# MB9BF12xJ register map
File version: 1.2
CPU: 
Registers are 8-bit, read-write, reset 0x0 unless marked. A register's access mark holds for its fields unless they carry their own. Offsets are from the block's base; [hi:lo] are bit positions; {n}, {i} and the like mark numbered series.

## EXTI — External Interrupt and NMI Control
Base 0x40030000
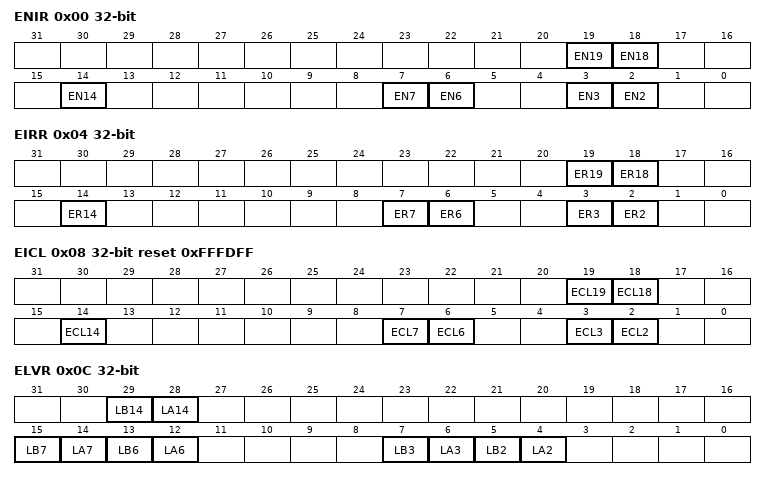
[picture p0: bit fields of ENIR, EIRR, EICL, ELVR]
0x00 ENIR 32-bit — Enable Interrupt Request Register
  [19] EN19 — Bit19 of ENIR
  [18] EN18 — Bit18 of ENIR
  [14] EN14 — Bit14 of ENIR
  [7] EN7 — Bit7 of ENIR
  [6] EN6 — Bit6 of ENIR
  [3] EN3 — Bit3 of ENIR
  [2] EN2 — Bit2 of ENIR
0x04 EIRR 32-bit ro reset not defined — External Interrupt Request Register
  [19] ER19 rw — Bit19 of EIRR
  [18] ER18 rw — Bit18 of EIRR
  [14] ER14 — Bit14 of EIRR
  [7] ER7 — Bit7 of EIRR
  [6] ER6 — Bit6 of EIRR
  [3] ER3 — Bit3 of EIRR
  [2] ER2 — Bit2 of EIRR
0x08 EICL 32-bit reset 0xFFFDFF — External Interrupt Clear Register
  [19] ECL19 — Bit19 of EICL
  [18] ECL18 — Bit18 of EICL
  [14] ECL14 — Bit14 of EICL
  [7] ECL7 — Bit7 of EICL
  [6] ECL6 — Bit6 of EICL
  [3] ECL3 — Bit3 of EICL
  [2] ECL2 — Bit2 of EICL
0x0C ELVR 32-bit — External Interrupt Level Register
  [29] LB14 — Bit29 of ELVR
  [28] LA14 — Bit28 of ELVR
  [15] LB7 — Bit15 of ELVR
  [14] LA7 — Bit14 of ELVR
  [13] LB6 — Bit13 of ELVR
  [12] LA6 — Bit12 of ELVR
  [7] LB3 — Bit7 of ELVR
  [6] LA3 — Bit6 of ELVR
  [5] LB2 — Bit5 of ELVR
  [4] LA2 — Bit4 of ELVR
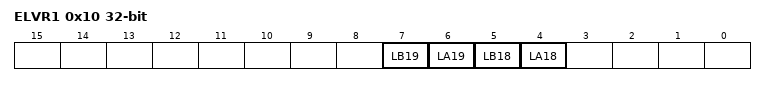
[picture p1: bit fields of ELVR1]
0x10 ELVR1 32-bit — External Interrupt Level Register 1
  [7] LB19 — Bit7 of ELVR1
  [6] LA19 — Bit6 of ELVR1
  [5] LB18 — Bit5 of ELVR1
  [4] LA18 — Bit4 of ELVR1
0x14 NMIRR ro — Non Maskable Interrupt Request Register
  [0] NR — NMI interrupt request detection bit
0x18 NMICL reset 0x1 — Non Maskable Interrupt Clear Register
  [0] NCL — NMI interrupt cause clear bit

## LVD — Low-voltage Detection
Base 0x40035000
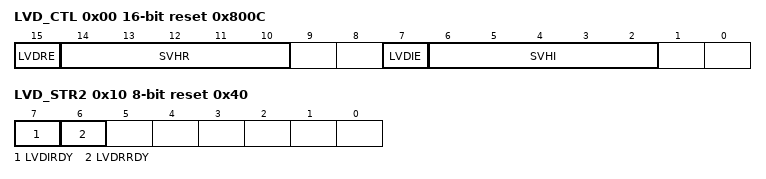
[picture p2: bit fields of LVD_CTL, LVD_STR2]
0x00 LVD_CTL 16-bit reset 0x800C — Low-voltage Detection Voltage Control Register
  [15] LVDRE — Low-voltage detection reset operation enable bit
  [14:10] SVHR — Low-voltage detection reset voltage setting bits
  [7] LVDIE — Low-voltage detection interrupt enable bit
  [6:2] SVHI — Low-voltage detection interrupt voltage setting bits
0x04 LVD_STR ro — Low-voltage Detection Interrupt Register
  [7] LVDIR — Low-voltage detection interrupt bit
0x08 LVD_CLR reset 0x80 — Low-voltage Detection Interrupt Clear Register
  [7] LVDCL — Low-voltage detection interrupt clear bit
0x0C LVD_RLR 32-bit reset 0x1 — Low-voltage Detection Voltage Protection Register
  [31:0] LVDLCK — Low-voltage Detection Voltage Control Register protection bits
0x10 LVD_STR2 ro reset 0x40 — Low-voltage Detection Circuit Status Register
  [7] LVDIRDY — Low-voltage detection interrupt status flag
  [6] LVDRRDY — Low-voltage detection reset status flag

## DS — Low Power Consumption Mode
Base 0x40035100
0x00 REG_CTL reset 0x4 — Sub Oscillation Circuit Power Supply Control Register
  [2:1] ISUBSEL — Sub oscillation circuit current setting bits
0x04 RCK_CTL reset 0x1 — Sub Clock Control Register
  [0] RTCCKE — RTC clock control bit
0x700 PMD_CTL — RTC Mode Control Register
  [0] RTCE — RTC mode control bit

## DMAC — DMAC Registers
Base 0x40060000
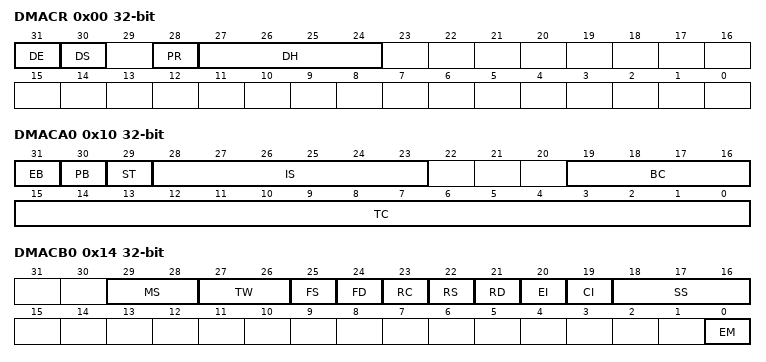
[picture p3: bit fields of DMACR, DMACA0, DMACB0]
0x00 DMACR 32-bit — Entire DMAC Configuration Register
  [31] DE — DMA Enable (all-channel operation enable bit)
  [30] DS — DMA Stop
  [28] PR — Priority Rotation
  [27:24] DH — DMA Halt (All-channel pause bit)
0x10 DMACA0 32-bit — Configuration A Register
  [31] EB — Enable bit (individual-channel operation enable bit)
  [30] PB — Pause bit (individual-channel pause bit)
  [29] ST — Software Trigger
  [28:23] IS — Input Select
  [19:16] BC — Block Count
  [15:0] TC — Transfer Count
0x14 DMACB0 32-bit — Configuration B Register
  [29:28] MS — Mode Select
  [27:26] TW — Transfer Width
  [25] FS — Fixed Source
  [24] FD — Fixed Destination
  [23] RC — Reload Count (BC/TC reload)
  [22] RS — Reload Source
  [21] RD — Reload Destination
  [20] EI — Error Interrupt (unsuccessful transfer completion interrupt enable)
  [19] CI — Completion Interrupt (successful transfer completion interrupt enable)
  [18:16] SS — Stop Status (stop status notification)
  [0] EM — Enable bit Mask (EB bit clear mask)
0x18 DMACSA0 32-bit — Transfer Source Address Register
0x1C DMACDA0 32-bit — Transfer Destination Address Register
{0x10+0x10*i} DMACA{i} 32-bit reset not defined (i=1..3) — Configuration A Register {i}
{0x14+0x10*i} DMACB{i} 32-bit reset not defined (i=1..3) — Configuration B Register {i}
{0x18+0x10*i} DMACSA{i} 32-bit reset not defined (i=1..3) — Transfer Source Address Register {i}
{0x1C+0x10*i} DMACDA{i} 32-bit reset not defined (i=1..3) — Transfer Destination Address Register {i}
